AUTOSAR XML (schema 4-0-3)
package /ComponentTypes
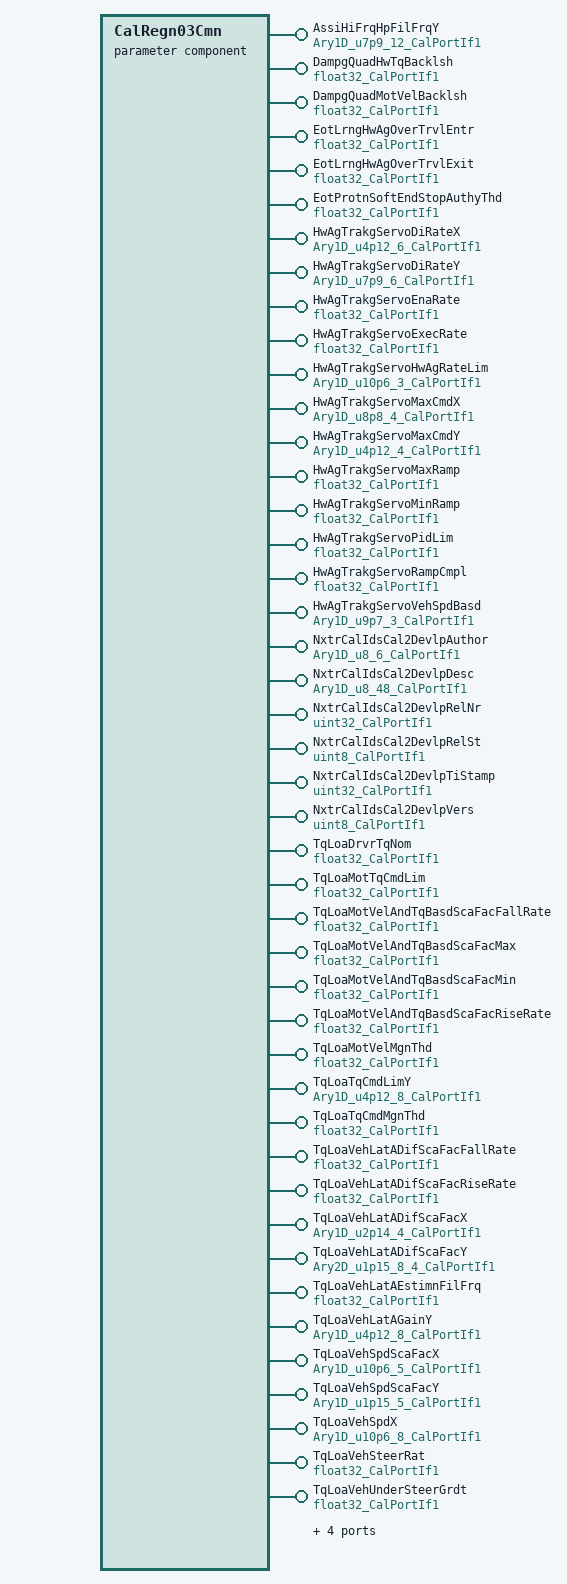
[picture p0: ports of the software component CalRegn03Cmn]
  parameter sw component type CalRegn03Cmn
    48 x provide port:
      AssiHiFrqHpFilFrqY: parameter-provide-com-spec{init-value=12 x 4096, parameter=Ary1D}, provided-interface=Ary1D_u7p9_12_CalPortIf1
      DampgQuadHwTqBacklsh: parameter-provide-com-spec{init-value=0, parameter=Val}, provided-interface=float32_CalPortIf1
      DampgQuadMotVelBacklsh: parameter-provide-com-spec{init-value=0, parameter=Val}, provided-interface=float32_CalPortIf1
      EotLrngHwAgOverTrvlEntr: parameter-provide-com-spec{init-value=646, parameter=Val}, provided-interface=float32_CalPortIf1
      EotLrngHwAgOverTrvlExit: parameter-provide-com-spec{init-value=632, parameter=Val}, provided-interface=float32_CalPortIf1
      EotProtnSoftEndStopAuthyThd: parameter-provide-com-spec{init-value=0.9, parameter=Val}, provided-interface=float32_CalPortIf1
      HwAgTrakgServoDiRateX: parameter-provide-com-spec{init-value=[0, 4096, 8192, 12288, 16384, 28672], parameter=Ary1D}, provided-interface=Ary1D_u4p12_6_CalPortIf1
      HwAgTrakgServoDiRateY: parameter-provide-com-spec{init-value=[154, 205, 256, 512, 1024, 2560], parameter=Ary1D}, provided-interface=Ary1D_u7p9_6_CalPortIf1
      HwAgTrakgServoEnaRate: parameter-provide-com-spec{init-value=0, parameter=Val}, provided-interface=float32_CalPortIf1
      HwAgTrakgServoExecRate: parameter-provide-com-spec{init-value=500, parameter=Val}, provided-interface=float32_CalPortIf1
      HwAgTrakgServoHwAgRateLim: parameter-provide-com-spec{init-value=[38400, 38400, 38400], parameter=Ary1D}, provided-interface=Ary1D_u10p6_3_CalPortIf1
      HwAgTrakgServoMaxCmdX: parameter-provide-com-spec{init-value=[0, 1280, 3072, 3098], parameter=Ary1D}, provided-interface=Ary1D_u8p8_4_CalPortIf1
      HwAgTrakgServoMaxCmdY: parameter-provide-com-spec{init-value=[36045, 36045, 36045, 36045], parameter=Ary1D}, provided-interface=Ary1D_u4p12_4_CalPortIf1
      HwAgTrakgServoMaxRamp: parameter-provide-com-spec{init-value=1, parameter=Val}, provided-interface=float32_CalPortIf1
      HwAgTrakgServoMinRamp: parameter-provide-com-spec{init-value=0, parameter=Val}, provided-interface=float32_CalPortIf1
      HwAgTrakgServoPidLim: parameter-provide-com-spec{init-value=3.2578125, parameter=Val}, provided-interface=float32_CalPortIf1
      HwAgTrakgServoRampCmpl: parameter-provide-com-spec{init-value=0, parameter=Val}, provided-interface=float32_CalPortIf1
      HwAgTrakgServoVehSpdBasd: parameter-provide-com-spec{init-value=[0, 256, 640], parameter=Ary1D}, provided-interface=Ary1D_u9p7_3_CalPortIf1
      NxtrCalIdsCal2DevlpAuthor: parameter-provide-com-spec{init-value=6 x 0, parameter=Ary1D}, provided-interface=Ary1D_u8_6_CalPortIf1
      NxtrCalIdsCal2DevlpDesc: parameter-provide-com-spec{init-value=48 x 0, parameter=Ary1D}, provided-interface=Ary1D_u8_48_CalPortIf1
      NxtrCalIdsCal2DevlpRelNr: parameter-provide-com-spec{init-value=0, parameter=Val}, provided-interface=uint32_CalPortIf1
      NxtrCalIdsCal2DevlpRelSt: parameter-provide-com-spec{init-value=0, parameter=Val}, provided-interface=uint8_CalPortIf1
      NxtrCalIdsCal2DevlpTiStamp: parameter-provide-com-spec{init-value=0, parameter=Val}, provided-interface=uint32_CalPortIf1
      NxtrCalIdsCal2DevlpVers: parameter-provide-com-spec{init-value=0, parameter=Val}, provided-interface=uint8_CalPortIf1
      TqLoaDrvrTqNom: parameter-provide-com-spec{init-value=0.0117, parameter=Val}, provided-interface=float32_CalPortIf1
      TqLoaMotTqCmdLim: parameter-provide-com-spec{init-value=4.5, parameter=Val}, provided-interface=float32_CalPortIf1
      TqLoaMotVelAndTqBasdScaFacFallRate: parameter-provide-com-spec{init-value=-15.625, parameter=Val}, provided-interface=float32_CalPortIf1
      TqLoaMotVelAndTqBasdScaFacMax: parameter-provide-com-spec{init-value=1, parameter=Val}, provided-interface=float32_CalPortIf1
      TqLoaMotVelAndTqBasdScaFacMin: parameter-provide-com-spec{init-value=0.75, parameter=Val}, provided-interface=float32_CalPortIf1
      TqLoaMotVelAndTqBasdScaFacRiseRate: parameter-provide-com-spec{init-value=7.8125, parameter=Val}, provided-interface=float32_CalPortIf1
      TqLoaMotVelMgnThd: parameter-provide-com-spec{init-value=1.908, parameter=Val}, provided-interface=float32_CalPortIf1
      TqLoaTqCmdLimY: parameter-provide-com-spec{init-value=[2880, 2880, 2880, 2240, 1664, 1408, 1216, 832], parameter=Ary1D}, provided-interface=Ary1D_u4p12_8_CalPortIf1
      TqLoaTqCmdMgnThd: parameter-provide-com-spec{init-value=0, parameter=Val}, provided-interface=float32_CalPortIf1
      TqLoaVehLatADifScaFacFallRate: parameter-provide-com-spec{init-value=-4, parameter=Val}, provided-interface=float32_CalPortIf1
      TqLoaVehLatADifScaFacRiseRate: parameter-provide-com-spec{init-value=0.1, parameter=Val}, provided-interface=float32_CalPortIf1
      TqLoaVehLatADifScaFacX: parameter-provide-com-spec{init-value=[0, 2294, 5243, 16384], parameter=Ary1D}, provided-interface=Ary1D_u2p14_4_CalPortIf1
      TqLoaVehLatADifScaFacY: parameter-provide-com-spec{init-value=8 x [32768, 32768, 0, 0], parameter=Ary2D}, provided-interface=Ary2D_u1p15_8_4_CalPortIf1
      TqLoaVehLatAEstimnFilFrq: parameter-provide-com-spec{init-value=2, parameter=Val}, provided-interface=float32_CalPortIf1
      TqLoaVehLatAGainY: parameter-provide-com-spec{init-value=[0, 6144, 9920, 6784, 4928, 3968, 3520, 384], parameter=Ary1D}, provided-interface=Ary1D_u4p12_8_CalPortIf1
      TqLoaVehSpdScaFacX: parameter-provide-com-spec{init-value=[320, 640, 1920, 3840, 6400], parameter=Ary1D}, provided-interface=Ary1D_u10p6_5_CalPortIf1
      TqLoaVehSpdScaFacY: parameter-provide-com-spec{init-value=[0, 32768, 32768, 32768, 32768], parameter=Ary1D}, provided-interface=Ary1D_u1p15_5_CalPortIf1
      TqLoaVehSpdX: parameter-provide-com-spec{init-value=[320, 640, 1280, 1920, 2560, 3200, 3840, 7680], parameter=Ary1D}, provided-interface=Ary1D_u10p6_8_CalPortIf1
      TqLoaVehSteerRat: parameter-provide-com-spec{init-value=16, parameter=Val}, provided-interface=float32_CalPortIf1
      TqLoaVehUnderSteerGrdt: parameter-provide-com-spec{init-value=0.0211, parameter=Val}, provided-interface=float32_CalPortIf1
      TqLoaVehWhlBas: parameter-provide-com-spec{init-value=2.7305, parameter=Val}, provided-interface=float32_CalPortIf1
      WhlImbRejctnCmdMgnLp1FilFrq: parameter-provide-com-spec{init-value=5, parameter=Val}, provided-interface=float32_CalPortIf1
      WhlImbRejctnCmdMgnLp2FilFrq: parameter-provide-com-spec{init-value=5, parameter=Val}, provided-interface=float32_CalPortIf1
      WhlImbRejctnDcTrendLpFil: parameter-provide-com-spec{init-value=0.2, parameter=Val}, provided-interface=float32_CalPortIf1
